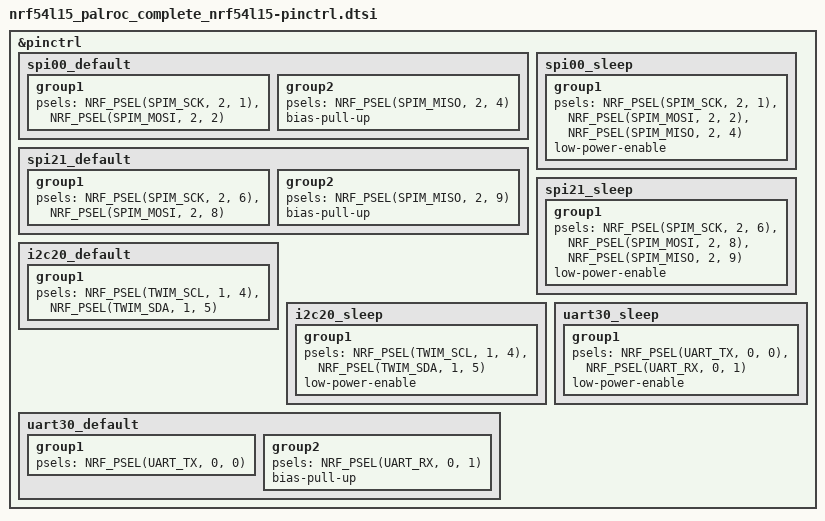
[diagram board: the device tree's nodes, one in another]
/*
 * Copyright (c) 2024 Nordic Semiconductor ASA
 * SPDX-License-Identifier: Apache-2.0
 */

&pinctrl {

	/omit-if-no-ref/ spi00_default: spi00_default {
		group1 {
			psels = <NRF_PSEL(SPIM_SCK, 2, 1)>,
				<NRF_PSEL(SPIM_MOSI, 2, 2)>;
		};

		group2 {
			psels = <NRF_PSEL(SPIM_MISO, 2, 4)>;
			bias-pull-up;
		};
	};

	/omit-if-no-ref/ spi00_sleep: spi00_sleep {
		group1 {
			psels = <NRF_PSEL(SPIM_SCK, 2, 1)>,
				<NRF_PSEL(SPIM_MOSI, 2, 2)>,
				<NRF_PSEL(SPIM_MISO, 2, 4)>;
			low-power-enable;
		};
	};

	/omit-if-no-ref/ spi21_default: spi21_default {
		group1 {
			psels = <NRF_PSEL(SPIM_SCK, 2, 6)>,
				<NRF_PSEL(SPIM_MOSI, 2, 8)>;
		};

		group2 {
			psels = <NRF_PSEL(SPIM_MISO, 2, 9)>;
			bias-pull-up;
		};
	};

	/omit-if-no-ref/ spi21_sleep: spi21_sleep {
		group1 {
			psels = <NRF_PSEL(SPIM_SCK, 2, 6)>,
				<NRF_PSEL(SPIM_MOSI, 2, 8)>,
				<NRF_PSEL(SPIM_MISO, 2, 9)>;
			low-power-enable;
		};
	};

	/omit-if-no-ref/ i2c20_default: i2c20_default {
		group1 {
			psels = <NRF_PSEL(TWIM_SCL, 1, 4)>,
				<NRF_PSEL(TWIM_SDA, 1, 5)>;
		};
	};

	/omit-if-no-ref/ i2c20_sleep: i2c20_sleep {
		group1 {
			psels = <NRF_PSEL(TWIM_SCL, 1, 4)>,
				<NRF_PSEL(TWIM_SDA, 1, 5)>;
			low-power-enable;
		};
	};

	/* uart30 pinctrl — TX/RX only. CTS/RTS are intentionally NOT mapped here
	 * because the inter-MCU link uses nrf-sw-lpuart (REQ/RDY GPIOs replace
	 * hardware flow control). The CTS/RTS lines on P0.02 / P0.03 remain
	 * physically wired as a backup pair — if REQ/RDY misbehave, retarget
	 * the lpuart child in the common dtsi to those pins.
	 */
	/omit-if-no-ref/ uart30_default: uart30_default {
		group1 {
			psels = <NRF_PSEL(UART_TX, 0, 0)>;
		};

		group2 {
			psels = <NRF_PSEL(UART_RX, 0, 1)>;
			bias-pull-up;
		};
	};

	/omit-if-no-ref/ uart30_sleep: uart30_sleep {
		group1 {
			psels = <NRF_PSEL(UART_TX, 0, 0)>,
				<NRF_PSEL(UART_RX, 0, 1)>;
			low-power-enable;
		};
	};
};
